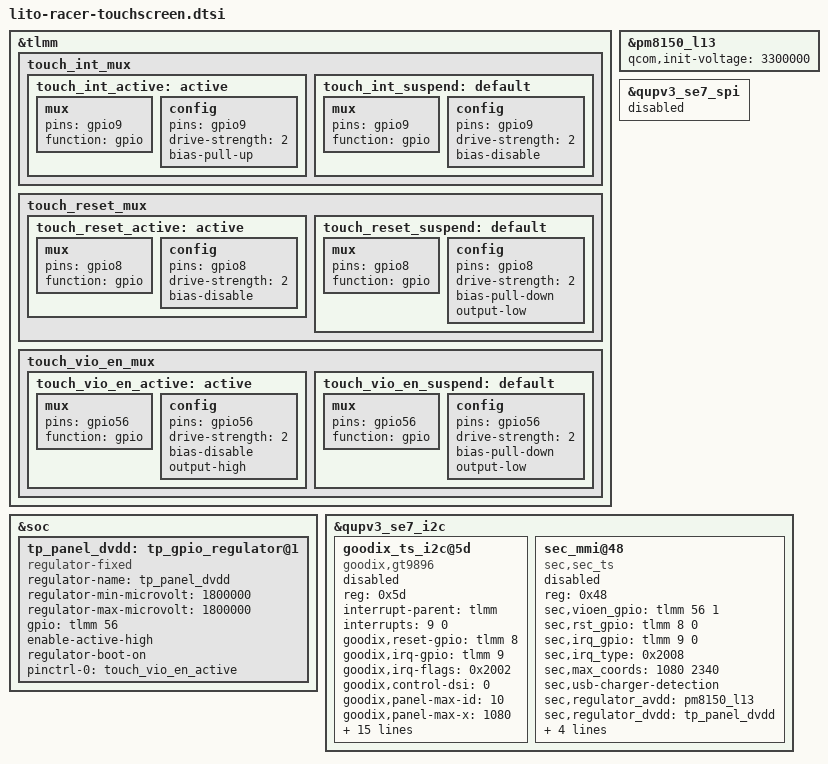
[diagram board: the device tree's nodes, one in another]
&tlmm {
	touch_int_mux {
		touch_int_active: active {
			mux {
				pins = "gpio9";
				function = "gpio";
			};
			config {
				pins = "gpio9";
				drive-strength = <2>;
				bias-pull-up;
			};
		};

		touch_int_suspend: default {
			mux {
				pins = "gpio9";
				function = "gpio";
			};
			config {
				pins = "gpio9";
				drive-strength = <2>;
				bias-disable;
			};
		};
	};

	touch_reset_mux {
		touch_reset_active: active {
			mux {
				pins = "gpio8";
				function = "gpio";
			};
			config {
				pins = "gpio8";
				drive-strength = <2>;
				bias-disable;
			};
		};

		touch_reset_suspend: default {
			mux {
				pins = "gpio8";
				function = "gpio";
			};
			config {
				pins = "gpio8";
				drive-strength = <2>;
				bias-pull-down;
				output-low;
			};
		};
	};

	touch_vio_en_mux {
		touch_vio_en_active: active {
			mux {
				pins = "gpio56";
				function = "gpio";
			};
			config {
				pins = "gpio56";
				drive-strength = <2>;
				bias-disable;
				output-high;
			};
		};

		touch_vio_en_suspend: default {
			mux {
				pins = "gpio56";
				function = "gpio";
			};
			config {
				pins = "gpio56";
				drive-strength = <2>;
				bias-pull-down;
				output-low;
			};
		};
	};
};

&soc {
	tp_panel_dvdd: tp_gpio_regulator@1 {
		compatible = "regulator-fixed";
		regulator-name = "tp_panel_dvdd";
		regulator-min-microvolt = <1800000>;
		regulator-max-microvolt = <1800000>;
		//regulator-enable-ramp-delay = <233>;
		gpio = <&tlmm 56 0>;
		enable-active-high;
		regulator-boot-on;
		pinctrl-names = "default";
		pinctrl-0 = <&touch_vio_en_active>;
	};
};

&pm8150_l13 {
	qcom,init-voltage = <3300000>;
};

&qupv3_se7_spi {
	status = "disabled";
};

&qupv3_se7_i2c {
	status = "ok";
	goodix_ts_i2c@5d {
		compatible = "goodix,gt9896";
		reg = <0x5d>;
		status = "/chosen","mmi,panel_name","contains","boe_gdx","csot_gdx";
		interrupt-parent = <&tlmm>;
		interrupts = <9 0>;
		goodix,reset-gpio = <&tlmm 8 0x0>;
		goodix,irq-gpio = <&tlmm 9 0x2002>;
		goodix,irq-flags = <0x2002>; /* 1:trigger rising, 2:trigger falling;*/
		goodix,control-dsi = <0>;
		goodix,panel-max-id = <10>;
		goodix,panel-max-x = <1080>;
		goodix,panel-max-y = <2340>;
		goodix,panel-max-w = <256>;
		goodix,panel-max-p = <4096>;
		goodix,avdd-name = "pm8150_l13";
		goodix,iovdd-name = "tp_panel_dvdd";
		goodix,power-on-delay-us = <300000>; /*300ms*/
		goodix,power-off-delay-us = <5000>;
		/*goodix,swap-axis;*/
		goodix,usb_charger;
		goodix,cfg_bin_name = "goodix_cfg_group_boe_racerl.bin";
		goodix,fw_name = "goodix-gtx8-01-14-racerl.bin";
		pinctrl-names = "pmx_ts_active", "pmx_ts_suspend";
		pinctrl-0 = <&touch_reset_active &touch_int_active>;
		pinctrl-1 = <&touch_reset_suspend &touch_int_suspend>;
	};

	sec_mmi@48 {
		status = "/chosen", "mmi,panel_name","dsi_boe_667_1080p_cmd_display";
		compatible = "sec,sec_ts";
		reg = <0x48>;
		sec,vioen_gpio = <&tlmm 56 1>;
		sec,rst_gpio = <&tlmm 8 0>;
		sec,irq_gpio = <&tlmm 9 0>;
		sec,irq_type = <0x2008>; /*IRQF_TRIGGER_LOW | IRQF_ONESHOT*/
		sec,max_coords = <1080 2340>;
		sec,usb-charger-detection;
		sec,regulator_avdd = "pm8150_l13";
		sec,regulator_dvdd = "tp_panel_dvdd";
		pinctrl-names = "on_state", "off_state";
		pinctrl-0 = <&touch_reset_active &touch_int_active>;
		pinctrl-1 = <&touch_reset_suspend &touch_int_suspend>;
	};
};
